# ospi_secure register map
Vendor: Texas Instruments
Peripheral module from a debugger description file (folder CC35X1E).
Registers are 32-bit, access per field, reset 0x0 unless marked. A register's access mark holds for its fields unless they carry their own. Offsets are as the file gives them; lines under a group give offsets from that group; [hi:lo] are bit positions; {n}, {i} and the like mark numbered series; 'fields as' and 'values as' point back to an identical list; <NAME> marks a mode.

## ospi_secure
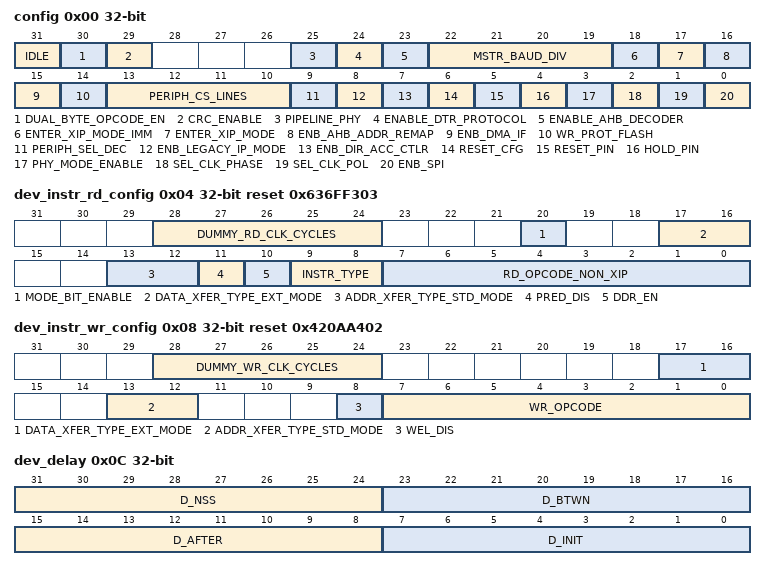
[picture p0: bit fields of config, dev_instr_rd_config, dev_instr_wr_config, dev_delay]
0x00 config reset not defined — Octal-SPI Configuration Register
  [31] IDLE ro — Serial interface and low level SPI pipeline is IDLE: This is a STATUS read-only bit. Note this is a retimed signal, so there will be some inherent delay on the generation of this status signal.
    0=DISABLE; 1=ENABLE
  [30] DUAL_BYTE_OPCODE_EN rw — Dual-byte Opcode Mode enable bit This bit is to be set in case the target Flash Device supports dual byte opcode (i.e. Macronix MX25). It is applicable for Octal I/O Mode or Protocol only so should be set back to low if the device is configured to work in another SPI Mode. If enabled, the supplementing bytes are taken from Opcode Extension Register (Lower) and from Opcode Extension Register (Upper).
    0=DISABLE; 1=ENABLE
  [29] CRC_ENABLE rw — CRC enable bit This bit is to be set in case the target Flash Device supports CRC (Macronix MX25). It is applicable for Octal DDR Protocol only so should be set back to low if the device is configured to work in another SPI Mode.
    0=DISABLE; 1=ENABLE
  [25] PIPELINE_PHY rw — Pipeline PHY Mode enable: This bit is relevant only for configuration with PHY Module. It should be asserted to '1' between consecutive PHY pipeline reads transfers and de-asserted to '0' otherwise.
    0=DISABLE; 1=ENABLE
  [24] ENABLE_DTR_PROTOCOL rw — Enable DTR Protocol: This bit should be set if device is configured to work in DTR protocol.
    0=DISABLE; 1=ENABLE
  [23] ENABLE_AHB_DECODER rw — Enable AHB Decoder: Value=0 : Active slave is selected based on Peripheral Chip Select Lines (bits [13:10]). Value=1 Active slave is selected based on actual AHB address (the partition for each device is calculated with respect to bits [28:21] of Device Size Configuration Register)
    0=DISABLE; 1=ENABLE
  [22:19] MSTR_BAUD_DIV rw — Master Mode Baud Rate Divisor: SPI baud rate = (master reference clock) baud_rate_divisor. The baud rate is the clock rate divided by 2 multiplied by (Divisor + 1). Meaning, when Divisor Value is set to 0,1,2,..15 it sets the baud rate is the clock rate divided by 2, 4, 6,..32 respectively
    0=MINIMUM (Smallest value); 15=MAXIMUM (Highest possible value)
  [18] ENTER_XIP_MODE_IMM rw — Enter XIP Mode immediately: Value=0 : If XIP is enabled, then setting to 0 will cause the controller to exit XIP mode on the next READ instruction. Value=1 : Operate the device in XIP mode immediately Use this register when the external device wakes up in XIP mode (as per the contents of its non- volatile configuration register). The controller will assume the next READ instruction will be passed to the device as an XIP instruction, and therefore will not require the READ opcode to be transferred. Note: To exit XIP mode, this bit should be set to 0. This will take effect in the attached device only after the next READ instruction is executed. Software therefore should ensure that at least one READ instruction is requested after resetting this bit in order to be sure that XIP mode is exited.
    0=DISABLE; 1=ENABLE
  [17] ENTER_XIP_MODE rw — Enter XIP Mode on next READ: Value=0 : If XIP is enabled, then setting to 0 will cause the controller to exit XIP mode on the next READ instruction. Value=1 : If XIP is disabled, then setting to ?1? will inform the controller that the device is ready to enter XIP on the next READ instruction. The controller will therefore send the appropriate command sequence, including mode bits to cause the device to enter XIP mode. Use this register after the controller has ensured the FLASH device has been configured to be ready to enter XIP mode. Note : To exit XIP mode, this bit should be set to 0. This will take effect in the attached device only AFTER the next READ instruction is executed. Software should therefore ensure that at least one READ instruction is requested after resetting this bit before it can be sure XIP mode in the device is exited.
    0=DISABLE; 1=ENABLE
  [16] ENB_AHB_ADDR_REMAP rw — Enable AHB Address Re-mapping: (Direct Access Mode Only) When set to 1, the incoming AHB address will be adapted and sent to the FLASH device as (address + N), where N is the value stored in the remap address register.
    0=DISABLE; 1=ENABLE
  [15] ENB_DMA_IF rw — Enable DMA Peripheral Interface: Set to 1 to enable the DMA handshaking logic. When enabled the controller will trigger DMA transfer requests via the DMA peripheral interface. Set to 0 to disable
    0=DISABLE; 1=ENABLE
  [14] WR_PROT_FLASH rw — Write Protect Flash Pin: Set to drive the Write Protect pin of the FLASH device. This is resynchronized to the generated memory clock as necessary.
    0=DISABLE; 1=ENABLE
  [13:10] PERIPH_CS_LINES rw — Peripheral Chip Select Lines: Peripheral chip select lines If pdec = 0, ss[3:0] are output thus: ss[3:0] n_ss_out[3:0] xxx0 1110 xx01 1101 x011 1011 0111 0111 1111 1111 (no peripheral selected) else ss[3:0] directly drives n_ss_out[3:0]
    values as MSTR_BAUD_DIV
  [9] PERIPH_SEL_DEC rw — Peripheral select decode:
    0=DISABLE (only 1 of 4 selects n_ss_out[3:0] is active 1 : allow external 4-to-16 decode (n_ss_out = ss)); 1=ENABLE (allow external 4-to-16 decode (n_ss_out = ss))
  [8] ENB_LEGACY_IP_MODE rw — Legacy IP Mode Enable:
    0=DISABLE (Use Direct Access Controller/Indirect Access Controller 1 : legacy Mode is enabled. In this mode, any write to the controller via the AHB interface is serialized and sent to the FLASH device. Any valid AHB read will pop the internal RX-FIFO, retrieving data that was forwarded by the external FLASH device on the SPI lines,4,2 or 1 byte transfers are permitted and controlled via the HSIZE input.); 1=ENABLE (legacy Mode is enabled. In this mode, any write to the controller via the AHB interface is serialized and sent to the FLASH device. Any valid AHB read will pop the internal RX-FIFO, retrieving data that was forwarded by the external FLASH device on the SPI lines,4,2 or 1 byte transfers are permitted and controlled via the HSIZE input.)
  [7] ENB_DIR_ACC_CTLR rw — Enable Direct Access Controller:
    0=DISABLE (disable the Direct Access Controller once current transfer of the data word (FF_W) is complete. 1 : enable the Direct Access Controller When the Direct Access Controller and Indirect Access Controller are both disabled, all AHB requested are completed with an error response.); 1=ENABLE (enable the Direct Access Controller When the Direct Access Controller and Indirect Access Controller are both disabled, all AHB requested are completed with an error response.)
  [6] RESET_CFG rw — RESET pin configuration: 0 = RESET feature on DQ3 pin of the device 1 = RESET feature on dedicated pin of the device (controlling of 5th bit influences on reset_out output)
    0=DISABLE; 1=ENABLE
  [5] RESET_PIN rw — Set to drive the RESET pin of the FLASH device and reset for de-activation of the RESET pin feature
    0=DISABLE; 1=ENABLE
  [4] HOLD_PIN rw — Set to drive the HOLD pin of the FLASH device and reset for de-activation of the HOLD pin feature
    0=DISABLE; 1=ENABLE
  [3] PHY_MODE_ENABLE rw — PHY mode enable: When enabled, the controller is informed that PHY Module is to be used for handling SPI transfers. This bit is relevant only for configuration with PHY Module.
    0=DISABLE; 1=ENABLE
  [2] SEL_CLK_PHASE rw — Select Clock Phase: Selects whether the clock is in an active or inactive phase outside the SPI word.
    0=DISABLE (the SPI clock is active outside the word 1 : the SPI clock is inactive outside the word); 1=ENABLE (the SPI clock is inactive outside the word)
  [1] SEL_CLK_POL rw — Clock polarity outside SPI word:
    0=DISABLE (the SPI clock is quiescent low 1 : the SPI clock is quiescent high); 1=ENABLE (the SPI clock is quiescent high)
  [0] ENB_SPI rw — Octal-SPI Enable:
    0=DISABLE (disable the Octal-SPI, once current transfer of the data word (FF_W) is complete. 1 : enable the Octal-SPI, when spi_enable = 0, all output enables are inactive and all pins are set to input mode.); 1=ENABLE (enable the Octal-SPI, when spi_enable = 0, all output enables are inactive and all pins are set to input mode.)
0x04 dev_instr_rd_config reset 0x636FF303 (reset mask 0xFFEFF3FF) — Device Read Instruction Configuration Register
  [28:24] DUMMY_RD_CLK_CYCLES rw — Dummy Read Clock Cycles: Number of dummy clock cycles required by device for read instruction.
    0=MINIMUM (Smallest value); 31=MAXIMUM (Highest possible value)
  [20] MODE_BIT_ENABLE rw — Mode Bit Enable: Set this field to 1 to ensure that the mode bits as defined in the Mode Bit Configuration register are sent following the address bytes.
    0=DISABLE; 1=ENABLE
  [17:16] DATA_XFER_TYPE_EXT_MODE rw — Data Transfer Type for Standard SPI modes: 0 : SIO mode data is shifted to the device on DQ0 only and from the device on DQ1 only 1 : Used for Dual Input/Output instructions. For data transfers, DQ0 and DQ1 are used as both inputs and outputs. 2 : Used for Quad Input/Output instructions. For data transfers, DQ0,DQ1,DQ2 and DQ3 are used as both inputs and outputs. 3 : Used for Quad Input/Output instructions. For data transfers, DQ[7:0] are used as both inputs and outputs.
    0=MINIMUM (Smallest value); 3=MAXIMUM (Highest possible value)
  [13:12] ADDR_XFER_TYPE_STD_MODE rw — Address Transfer Type for Standard SPI modes: 0 : Addresses can be shifted to the device on DQ0 only 1 : Addresses can be shifted to the device on DQ0 and DQ1 only 2 : Addresses can be shifted to the device on DQ0, DQ1, DQ2 and DQ3 3 : Addresses can be shifted to the device on DQ[7:0]
    values as DATA_XFER_TYPE_EXT_MODE
  [11] PRED_DIS rw — Predicted Read Disable Bit: Disable generation of predicted read when doing read accesses using Direct Mode
    0=DISABLE; 1=ENABLE
  [10] DDR_EN rw — DDR Enable: This is to inform that opcode from rd_opcode_non_xip_fld is compliant with one of the DDR READ Commands
    0=DISABLE; 1=ENABLE
  [9:8] INSTR_TYPE rw — Instruction Type: 0 : Use Standard SPI mode (instruction always shifted into the device on DQ0 only) 1 : Use DIO-SPI mode (Instructions always sent on DQ0 and DQ1) 2 : Use QIO-SPI mode (Instructions always sent on DQ0, DQ1, DQ2 and DQ3) 3 : Use Octal-IO-SPI mode (Instructions always sent on DQ[7:0])
    values as DATA_XFER_TYPE_EXT_MODE
  [7:0] RD_OPCODE_NON_XIP rw — Read Opcode in non-XIP mode: Read Opcode to use when not in XIP mode
    0=MINIMUM (Smallest value); 255=MAXIMUM (Highest possible value)
0x08 dev_instr_wr_config reset 0x420AA402 (reset mask 0xFFFFFEFF) — Device Write Instruction Configuration Register
  [28:24] DUMMY_WR_CLK_CYCLES rw — Dummy Write Clock Cycles: Number of dummy clock cycles required by device for write instruction.
    values as dev_instr_rd_config.DUMMY_RD_CLK_CYCLES
  [17:16] DATA_XFER_TYPE_EXT_MODE rw — Data Transfer Type for Standard SPI modes: 0 : SIO mode data is shifted to the device on DQ0 only and from the device on DQ1 only 1 : Used for Dual Input/Output instructions. For data transfers, DQ0 and DQ1 are used as both inputs and outputs. 2 : Used for Quad Input/Output instructions. For data transfers, DQ0,DQ1,DQ2 and DQ3 are used as both inputs and outputs. 3 : Used for Quad Input/Output instructions. For data transfers, DQ[7:0] are used as both inputs and outputs.
    values as dev_instr_rd_config.DATA_XFER_TYPE_EXT_MODE
  [13:12] ADDR_XFER_TYPE_STD_MODE rw — Address Transfer Type for Standard SPI modes: 0 : Addresses can be shifted to the device on DQ0 only 1 : Addresses can be shifted to the device on DQ0 and DQ1 only 2 : Addresses can be shifted to the device on DQ0, DQ1, DQ2 and DQ3 3 : Addresses can be shifted to the device on DQ[7:0]
    values as dev_instr_rd_config.DATA_XFER_TYPE_EXT_MODE
  [8] WEL_DIS rw — WEL Disable: This is to turn off automatic issuing of WEL Command before write operation for DAC or INDAC
    0=DISABLE; 1=ENABLE
  [7:0] WR_OPCODE rw — Write Opcode
    values as dev_instr_rd_config.RD_OPCODE_NON_XIP
0x0C dev_delay rw — Octal-SPI Device Delay Register: This register is used to introduce relative delays into the generation of the master output signals. All timings are defined in cycles of the SPI REFERENCE CLOCK/ext_clk, defined in this table as SPI master ref clock.
  [all] fields
    values as dev_instr_rd_config.RD_OPCODE_NON_XIP
  [31:24] D_NSS — Clock Delay for Chip Select Deassert: Delay in master reference clocks for the length that the master mode chip select outputs are de-asserted between transactions. The minimum delay is always SCLK period to ensure the chip select is never re-asserted within an SCLK period.
  [23:16] D_BTWN — Clock Delay for Chip Select Deactivation: Delay in master reference clocks between one chip select being de-activated and the activation of another. This is used to ensure a quiet period between the selection of two different slaves and requires the transmit FIFO to be empty.
  [15:8] D_AFTER — Clock Delay for Last Transaction Bit: Delay in master reference clocks between last bit of current transaction and deasserting the device chip select (n_ss_out). By default, the chip select will be deasserted on the cycle following the completion of the current transaction.
  [7:0] D_INIT — Clock Delay with n_ss_out: Delay in master reference clocks between setting n_ss_out low and first bit transfer.
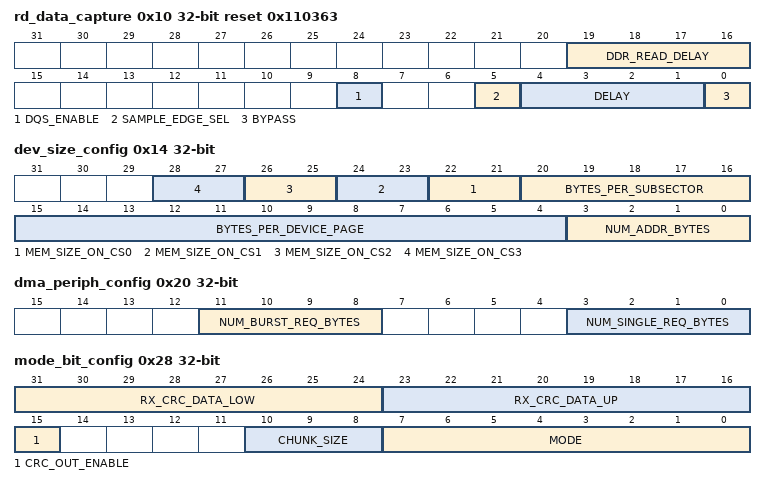
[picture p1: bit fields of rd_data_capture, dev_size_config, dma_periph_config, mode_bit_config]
0x10 rd_data_capture reset 0x110363 — Read Data Capture Register
  [19:16] DDR_READ_DELAY rw — DDR read delay: Delay the transmitted data by the programmed number of ref_clk cycles.This field is only relevant when DDR Read Command is executed. Otherwise can be ignored.
    values as config.MSTR_BAUD_DIV
  [8] DQS_ENABLE rw — DQS enable bit: If enabled, signal from DQS input is driven into RX DLL and is used for data capturing in PHY Mode rather than internally generated gated ref_clk..
    0=DISABLE; 1=ENABLE
  [5] SAMPLE_EDGE_SEL rw — Sample edge selection: Choose edge on which data outputs from flash memory will be sampled
    0=DISABLE; 1=ENABLE
  [4:1] DELAY rw — Read Delay: Delay the read data capturing logic by the programmed number of ref_clk cycles
    values as config.MSTR_BAUD_DIV
  [0] BYPASS rw — Bypass the adapted loopback clock circuit
    0=DISABLE; 1=ENABLE
0x14 dev_size_config reset not defined — Device Size Configuration Register
  [2n+22:2n+21] MEM_SIZE_ON_CS{n} rw (n=0..3) — Size of Flash Device connected to CS[{n}] pin: Value=00 : size of 512Mb. Value=01 : size of 1Gb. Value=10 : size of 2Gb. Value=11 : size of 4Gb.
    values as dev_instr_rd_config.DATA_XFER_TYPE_EXT_MODE
  [20:16] BYTES_PER_SUBSECTOR rw — Number of bytes per Block. This is required by the controller for performing the write protection logic. The number of bytes per block must be a power of 2 number.
    values as dev_instr_rd_config.DUMMY_RD_CLK_CYCLES
  [15:4] BYTES_PER_DEVICE_PAGE rw — Number of bytes per device page. This is required by the controller for performing FLASH writes up to and across page boundaries.
    0=MINIMUM (Smallest value); 0xFFF=MAXIMUM (Highest possible value)
  [3:0] NUM_ADDR_BYTES rw — Number of address bytes. A value of 0 indicates 1 byte.
    values as config.MSTR_BAUD_DIV
0x18 sram_partition_cfg reset 0x8080 — SRAM Partition Configuration Register
  [7:0] THRESHOLD rw — Defines the size of the indirect read partition in the SRAM, in units of SRAM locations. By default, half of the SRAM is reserved for indirect read operation, and half for indirect write. The size of this register will scale with the depth of the SRAM.
0x1C ind_ahb_addr_trigger rw — Indirect AHB Address Trigger Register
  [31:0] ADDR — This is the base address that will be used by the AHB controller. When the incoming AHB read access address matches a range of addresses from this trigger address to the trigger address + 15, then the AHB request will be completed by fetching data from the Indirect Controllers SRAM.
    0=MINIMUM (Smallest value); 0xFFFFFFFF=MAXIMUM (Highest possible value)
0x20 dma_periph_config — DMA Peripheral Configuration Register
  [11:8] NUM_BURST_REQ_BYTES rw — Number of Burst Bytes: Number of bytes in a burst type request on the DMA peripheral request. A programmed value of 0 represents a single byte. This should be setup before starting the indirect read or write operation. The actual number of bytes used is 2**(value in this register) which will simplify implementation.
    values as config.MSTR_BAUD_DIV
  [3:0] NUM_SINGLE_REQ_BYTES rw — Number of Single Bytes: Number of bytes in a single type request on the DMA peripheral request. A programmed value of 0 represents a single byte. This should be setup before starting the indirect read or write operation. The actual number of bytes used is 2**(value in this register) which will simplify implementation.
    values as config.MSTR_BAUD_DIV
0x24 remap_addr rw — Remap Address Register
  [31:0] VALUE — This register is used to remap an incoming AHB address to a different address used by the FLASH device.
    values as ind_ahb_addr_trigger.ADDR
0x28 mode_bit_config reset not defined — Mode Bit Configuration Register
  [31:24] RX_CRC_DATA_LOW ro — RX CRC data (lower) The first CRC byte returned after RX data chunk.
    values as dev_instr_rd_config.RD_OPCODE_NON_XIP
  [23:16] RX_CRC_DATA_UP ro — RX CRC data (upper) The second CRC byte returned after RX data chunk.
    values as dev_instr_rd_config.RD_OPCODE_NON_XIP
  [15] CRC_OUT_ENABLE rw — CRC# output enable bit When enabled, the controller expects the Flash Device to toggle CRC data on both SPI clock edges in CRC->CRC# sequence and calculates CRC compliance accordingly.
    0=DISABLE; 1=ENABLE
  [10:8] CHUNK_SIZE rw — It defines size of chunk after which CRC data is expected to show up on the SPI interface for write and read data transfers.
    0=MINIMUM (Smallest value); 7=MAXIMUM (Highest possible value)
  [7:0] MODE rw — These are the 8 mode bits that are sent to the device following the address bytes if mode bit transmission has been enabled.
    values as dev_instr_rd_config.RD_OPCODE_NON_XIP
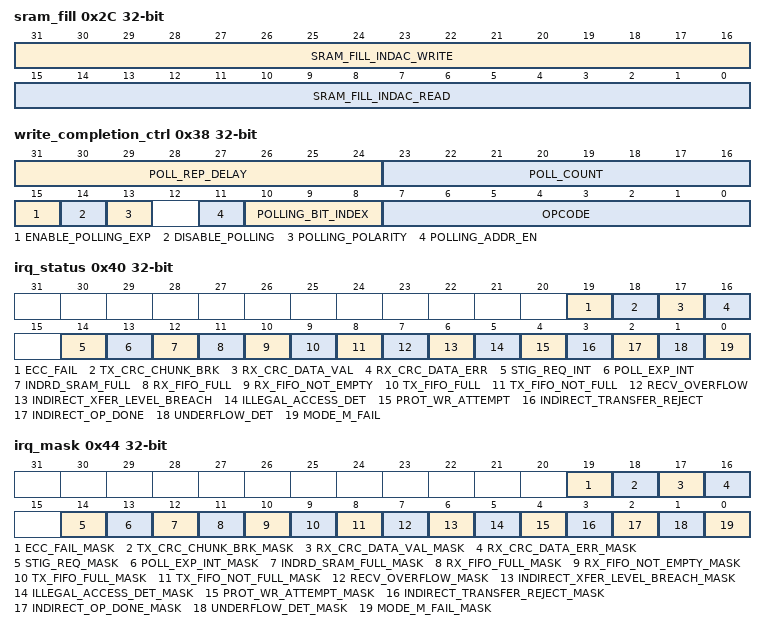
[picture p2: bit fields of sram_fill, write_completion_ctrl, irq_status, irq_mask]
0x2C sram_fill ro
  [31:16] SRAM_FILL_INDAC_WRITE — SRAM Fill Level (Indirect Write Partition): Identifies the current fill level of the SRAM Indirect Write partition
    0=MINIMUM (Smallest value); 0xFFFF=MAXIMUM (Highest possible value)
  [15:0] SRAM_FILL_INDAC_READ — SRAM Fill Level (Indirect Read Partition): Identifies the current fill level of the SRAM Indirect Read partition
    values as SRAM_FILL_INDAC_WRITE
0x30 tx_thresh reset 0x21 — TX Threshold Register
  [4:0] LEVEL rw — Defines the level at which the small TX FIFO not full interrupt is generated
    values as dev_instr_rd_config.DUMMY_RD_CLK_CYCLES
0x34 rx_thresh reset 0x21 — RX Threshold Register
  [4:0] LEVEL rw — Defines the level at which the small RX FIFO not empty interrupt is generated
    values as dev_instr_rd_config.DUMMY_RD_CLK_CYCLES
0x38 write_completion_ctrl reset not defined — Write Completion Control Register: This register defines how the controller will poll the device following a write transfer
  [31:24] POLL_REP_DELAY rw — Defines additional delay for maintain Chip Select de-asserted during auto-polling phase
    values as dev_instr_rd_config.RD_OPCODE_NON_XIP
  [23:16] POLL_COUNT rw — Defines the number of times the controller should expect to see a true result from the polling in successive reads of the device register.
    values as dev_instr_rd_config.RD_OPCODE_NON_XIP
  [15] ENABLE_POLLING_EXP rw — Set to '1' for enabling auto-polling expiration.
    0=DISABLE; 1=ENABLE
  [14] DISABLE_POLLING rw — This switches off the automatic polling function
    0=DISABLE; 1=ENABLE
  [13] POLLING_POLARITY rw — Defines the polling polarity. If '1', then the write transfer to the device will be complete if the polled bit is equal to '1'. If '0', then the write transfer to the device will be complete if the polled bit is equal to '0'.
    0=DISABLE; 1=ENABLE
  [11] POLLING_ADDR_EN rw — Enables address phase of auto-polling (Read Status) command.
    0=DISABLE; 1=ENABLE
  [10:8] POLLING_BIT_INDEX rw — Defines the bit index that should be polled. A value of 010 means that bit 2 of the returned data will be polled for.A value of 111 means that bit 7 of the returned data will be polled for.
    values as mode_bit_config.CHUNK_SIZE
  [7:0] OPCODE rw — Defines the opcode that should be issued by the controller when it is automatically polling for device program completion. This command is issued followed all device write operations. By default, this will poll the standard device STATUS register using opcode 0x05
    values as dev_instr_rd_config.RD_OPCODE_NON_XIP
0x3C no_of_polls_bef_exp rw reset 0xFFFFFFFF — Polling Expiration Register
  [31:0] NO_OF_POLLS_BEF_EXP — Number of polls cycles before expiration
    values as ind_ahb_addr_trigger.ADDR
0x40 irq_status — Interrupt Status Register: The status fields in this register are set when the described event occurs and the interrupt is enabled in the mask register. When any of these bit fields are set, the interrupt output is asserted high. The fields are each cleared by writing a 1 to the field. Note that bit fields 6 thru 10 are only valid when legacy SPI mode is active.
  [19] ECC_FAIL rw — ECC failure This interrupt informs the system that Flash Device reported ECC error.
    0=DISABLE; 1=ENABLE
  [18] TX_CRC_CHUNK_BRK rw — TX CRC chunk was broken This interrupt informs the system that program page SPI transfer was discontinued somewhere inside the chunk.
    0=DISABLE; 1=ENABLE
  [17] RX_CRC_DATA_VAL rw — RX CRC data valid New RX CRC data was captured from Flash Device
    0=DISABLE; 1=ENABLE
  [16] RX_CRC_DATA_ERR rw — RX CRC data error CRC data from Flash Device does not correspond to the one dynamically calculated by the controller.
    0=DISABLE; 1=ENABLE
  [14] STIG_REQ_INT rw — The controller is ready for getting another STIG request.
    0=DISABLE; 1=ENABLE
  [13] POLL_EXP_INT rw — The maximum number of programmed polls cycles is expired
    0=DISABLE; 1=ENABLE
  [12] INDRD_SRAM_FULL rw — Indirect Read Partition overflow: Indirect Read Partition of SRAM is full and unable to immediately complete indirect operation
    0=DISABLE; 1=ENABLE
  [11] RX_FIFO_FULL rw — Small RX FIFO full: Current FIFO status can be ignored in non-SPI legacy mode
    0=DISABLE (FIFO is not full 1 : FIFO is full); 1=ENABLE (FIFO is full)
  [10] RX_FIFO_NOT_EMPTY rw — Small RX FIFO not empty: Current FIFO status can be ignored in non-SPI legacy mode
    0=DISABLE (FIFO has less than RX THRESHOLD entries, 1 : FIFO has >= THRESHOLD entries); 1=ENABLE (FIFO has >= THRESHOLD entries)
  [9] TX_FIFO_FULL rw — Small TX FIFO full: Current FIFO status can be ignored in non-SPI legacy mode
    0=DISABLE (FIFO is not full, 1 : FIFO is full); 1=ENABLE (FIFO is full)
  [8] TX_FIFO_NOT_FULL rw — Small TX FIFO not full: Current FIFO status can be ignored in non-SPI legacy mode
    0=DISABLE (FIFO has >= THRESHOLD entries, 1 : FIFO has less than THRESHOLD entries); 1=ENABLE (FIFO has less than THRESHOLD entries)
  [7] RECV_OVERFLOW rw — Receive Overflow: This should only occur in Legacy SPI mode. Set if an attempt is made to push the RX FIFO when it is full. This bit is reset only by a system reset and cleared only when this register is read. If a new push to the RX FIFO occurs coincident with a register read this flag will remain set.
    0=DISABLE (no overflow has been detected. 1 : an overflow has occurred.); 1=ENABLE (an overflow has occurred.)
  [6] INDIRECT_XFER_LEVEL_BREACH rw — Indirect Transfer Watermark Level Breached
    0=DISABLE; 1=ENABLE
  [5] ILLEGAL_ACCESS_DET rw — Illegal AHB access has been detected. AHB wrapping bursts and the use of SPLIT/RETRY accesses will cause this error interrupt to trigger.
    0=DISABLE; 1=ENABLE
  [4] PROT_WR_ATTEMPT rw — Write to protected area was attempted and rejected.
    0=DISABLE; 1=ENABLE
  [3] INDIRECT_TRANSFER_REJECT rw — Indirect operation was requested but could not be accepted. Two indirect operations already in storage.
    0=DISABLE; 1=ENABLE
  [2] INDIRECT_OP_DONE rw — Indirect Operation Complete: Controller has completed last triggered indirect operation
    0=DISABLE; 1=ENABLE
  [1] UNDERFLOW_DET rw — Underflow Detected:
    0=DISABLE (no underflow has been detected 1 : underflow is detected and an attempt to transfer data is made when the small TX FIFO is empty. This may occur when AHB write data is being supplied too slowly to keep up with the requested write operation This bit is reset only by a system reset and cleared only when the register is read.); 1=ENABLE (underflow is detected and an attempt to transfer data is made when the small TX FIFO is empty. This may occur when AHB write data is being supplied too slowly to keep up with the requested write operation This bit is reset only by a system reset and cleared only when the register is read.)
  [0] MODE_M_FAIL rw — Mode M Failure: Mode M failure indicates the voltage on pin n_ss_in is inconsistent with the SPI mode. Set =1 if n_ss_in is low in master mode (multi-master contention). These conditions will clear the spi_enable bit and disable the SPI. This bit is reset only by a system reset and cleared only when this register is read.
    0=DISABLE (no mode fault has been detected 1 : a mode fault has occurred); 1=ENABLE (a mode fault has occurred)
0x44 irq_mask — Interrupt Mask: 0 : the interrupt for the corresponding interrupt status register bit is disabled. 1 : the interrupt for the corresponding interrupt status register bit is enabled.
  [all] fields
    0=DISABLE; 1=ENABLE
  [19] ECC_FAIL_MASK rw — ECC failure Mask
  [18] TX_CRC_CHUNK_BRK_MASK rw — TX CRC chunk was broken Mask
  [17] RX_CRC_DATA_VAL_MASK rw — RX CRC data valid Mask
  [16] RX_CRC_DATA_ERR_MASK rw — RX CRC data error Mask
  [14] STIG_REQ_MASK rw — STIG request completion Mask
  [13] POLL_EXP_INT_MASK rw — Polling expiration detected Mask
  [12] INDRD_SRAM_FULL_MASK rw — Indirect Read Partition overflow mask
  [11] RX_FIFO_FULL_MASK rw — Small RX FIFO full Mask
  [10] RX_FIFO_NOT_EMPTY_MASK rw — Small RX FIFO not empty Mask
  [9] TX_FIFO_FULL_MASK rw — Small TX FIFO full Mask
  [8] TX_FIFO_NOT_FULL_MASK rw — Small TX FIFO not full Mask
  [7] RECV_OVERFLOW_MASK rw — Receive Overflow Mask
  [6] INDIRECT_XFER_LEVEL_BREACH_MASK rw — Transfer Watermark Breach Mask
  [5] ILLEGAL_ACCESS_DET_MASK rw — Illegal Access Detected Mask
  [4] PROT_WR_ATTEMPT_MASK rw — Protected Area Write Attempt Mask
  [3] INDIRECT_TRANSFER_REJECT_MASK rw — Indirect Read Reject Mask
  [2] INDIRECT_OP_DONE_MASK rw — Indirect Complete Mask
  [1] UNDERFLOW_DET_MASK rw — Underflow Detected Mask
  [0] MODE_M_FAIL_MASK rw — Mode M Failure Mask
0x50 lower_wr_prot rw — Lower Write Protection Register
  [31:0] SUBSECTOR — The block number that defines the lower block in the range of blocks that is to be locked from writing. The definition of a block in terms of number of bytes is programmable via the Device Size Configuration register.
    values as ind_ahb_addr_trigger.ADDR
0x54 upper_wr_prot rw — Upper Write Protection Register
  [31:0] SUBSECTOR — The block number that defines the upper block in the range of blocks that is to be locked from writing. The definition of a block in terms of number of bytes is programmable via the Device Size Configuration register.
    values as ind_ahb_addr_trigger.ADDR
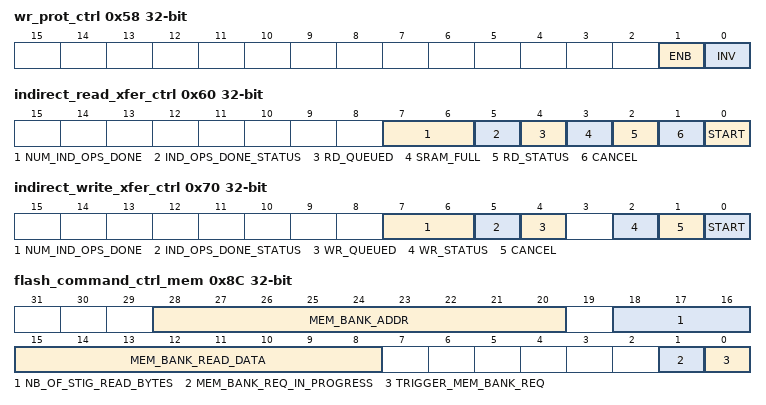
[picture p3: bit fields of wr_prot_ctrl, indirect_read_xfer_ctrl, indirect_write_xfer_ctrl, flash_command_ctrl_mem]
0x58 wr_prot_ctrl — Write Protection Control Register
  [1] ENB rw — Write Protection Enable Bit: When set to 1, any AHB write access with an address within the protection region defined in the lower and upper write protection registers is rejected. An AHB error response is generated and an interrupt source triggered. When set to 0, the protection region is disabled.
    0=DISABLE; 1=ENABLE
  [0] INV rw — Write Protection Inversion Bit: When set to 1, the protection region defined in the lower and upper write protection registers is inverted meaning it is the region that the system is permitted to write to. When set to 0, the protection region defined in the lower and upper write protection registers is the region that the system is not permitted to write to.
    0=DISABLE; 1=ENABLE
0x60 indirect_read_xfer_ctrl — Indirect Read Transfer Control Register
  [7:6] NUM_IND_OPS_DONE ro — This field contains the number of indirect operations which have been completed. This is used in conjunction with the indirect completion status field (bit 5). It is incremented by hardware when an indirect operation has completed. Write a 1 to bit 5 of this register to decrement it.
    values as dev_instr_rd_config.DATA_XFER_TYPE_EXT_MODE
  [5] IND_OPS_DONE_STATUS rw — Indirect Completion Status: This field is set to 1 when an indirect operation has completed. Write a 1 to this field to clear it.
    0=DISABLE; 1=ENABLE
  [4] RD_QUEUED ro — Two indirect read operations have been queued
    0=DISABLE; 1=ENABLE
  [3] SRAM_FULL rw — SRAM Full: SRAM full and unable to immediately complete an indirect operation. Write a 1 to this field to clear it.\"; indirect operation (status)
    0=DISABLE; 1=ENABLE
  [2] RD_STATUS ro — Indirect Read Status: Indirect read operation in progress (status)
    0=DISABLE; 1=ENABLE
  [1] CANCEL wo — Cancel Indirect Read: Writing a 1 to this bit will cancel all ongoing indirect read operations.
    0=DISABLE; 1=ENABLE
  [0] START wo — Start Indirect Read: Writing a 1 to this bit will trigger an indirect read operation. The assumption is that the indirect start address and the indirect number of bytes register is setup before triggering the indirect read operation.
    0=DISABLE; 1=ENABLE
0x64 indirect_read_xfer_watermark rw — Indirect Read Transfer Watermark Register
  [31:0] LEVEL — Watermark Value: This represents the minimum fill level of the SRAM before a DMA peripheral access is permitted. When the SRAM fill level passes the watermark, an interrupt is also generated. This field can be disabled by writing a value of all zeroes.
    values as ind_ahb_addr_trigger.ADDR
0x68 indirect_read_xfer_start rw — Indirect Read Transfer Start Address Register
  [31:0] ADDR — This is the start address from which the indirect access will commence its READ operation.
    values as ind_ahb_addr_trigger.ADDR
0x6C indirect_read_xfer_num_bytes rw — Indirect Read Transfer Number Bytes Register
  [31:0] VALUE — This is the number of bytes that the indirect access will consume. This can be bigger than the configured size of SRAM.
    values as ind_ahb_addr_trigger.ADDR
0x70 indirect_write_xfer_ctrl — Indirect Write Transfer Control Register
  [7:6] NUM_IND_OPS_DONE ro — This field contains the number of indirect operations which have been completed. This is used in conjunction with the indirect completion status field (bit 5). It is incremented by hardware when an indirect operation has completed. Write a 1 to bit 5 of this register to decrement it.
    values as dev_instr_rd_config.DATA_XFER_TYPE_EXT_MODE
  [5] IND_OPS_DONE_STATUS rw — Indirect Completion Status: This field is set to 1 when an indirect operation has completed. Write a 1 to this field to clear it.
    0=DISABLE; 1=ENABLE
  [4] WR_QUEUED ro — Two indirect write operations have been queued
    0=DISABLE; 1=ENABLE
  [2] WR_STATUS ro — Indirect Write Status: Indirect write operation in progress (status)
    0=DISABLE; 1=ENABLE
  [1] CANCEL wo — Cancel Indirect Write: Writing a 1 to this bit will cancel all ongoing indirect write operations.
    0=DISABLE; 1=ENABLE
  [0] START wo — Start Indirect Write: Writing a 1 to this bit will trigger an indirect write operation. The assumption is that the indirect start address and the indirect number of bytes register is setup before triggering the indirect write operation.
    0=DISABLE; 1=ENABLE
0x74 indirect_write_xfer_watermark rw reset 0xFFFFFFFF — Indirect Write Transfer Watermark Register
  [31:0] LEVEL — Watermark Value: This represents the maximum fill level of the SRAM before a DMA peripheral access is permitted. When the SRAM fill level falls below the watermark, an interrupt is also generated. This field can be disabled by writing a value of all ones.
    values as ind_ahb_addr_trigger.ADDR
0x78 indirect_write_xfer_start rw — Indirect Write Transfer Start Address Register
  [31:0] ADDR — Start of Indirect Access: This is the start address from which the indirect access will commence its READ operation.
    values as ind_ahb_addr_trigger.ADDR
0x7C indirect_write_xfer_num_bytes rw — Indirect Write Transfer Number Bytes Register
  [31:0] VALUE — Indirect Number of Bytes: This is the number of bytes that the indirect access will consume. This can be bigger than the configured size of SRAM.
    values as ind_ahb_addr_trigger.ADDR
0x80 indirect_trigger_addr_range reset 0x44 — Indirect Trigger Address Range Register
  [3:0] IND_RANGE_WIDTH rw — This is the address offset of Indirect Trigger Address Register.
    values as config.MSTR_BAUD_DIV
0x8C flash_command_ctrl_mem — Flash Command Control Memory Register
  [28:20] MEM_BANK_ADDR rw — The address of the Memory Bank which data will be read from.
    0=MINIMUM (Smallest value); 0x1FF=MAXIMUM (Highest possible value)
  [18:16] NB_OF_STIG_READ_BYTES rw — It defines the number of read bytes for the extended STIG.
    values as mode_bit_config.CHUNK_SIZE
  [15:8] MEM_BANK_READ_DATA ro — Last requested data from the STIG Memory Bank.
    values as dev_instr_rd_config.RD_OPCODE_NON_XIP
  [1] MEM_BANK_REQ_IN_PROGRESS ro — Memory Bank data request in progress.
    0=DISABLE; 1=ENABLE
  [0] TRIGGER_MEM_BANK_REQ wo — Trigger the Memory Bank data request.
    0=DISABLE; 1=ENABLE
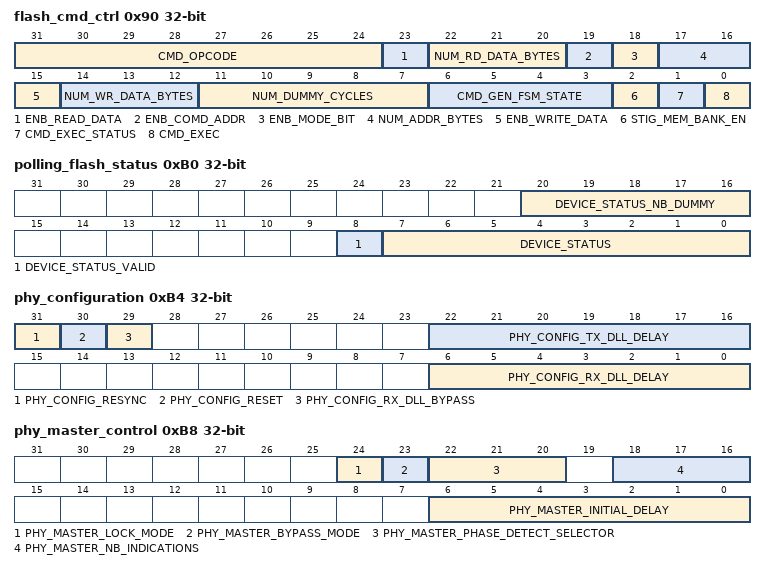
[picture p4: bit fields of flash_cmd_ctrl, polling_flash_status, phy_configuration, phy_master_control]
0x90 flash_cmd_ctrl — Flash Command Control Register
  [31:24] CMD_OPCODE rw — Command Opcode: The command opcode field should be setup before triggering the command. For example, 0x20 maps to SubSector Erase. Writing to the execute field (bit 0) of this register launches the command. NOTE : Using this approach to issue commands to the device will make use of the instruction type of the device instruction configuration register. If this field is set to 2'b00, then the command opcode, command address, command dummy bytes and command data will all be transferred in a serial fashion. If this field is set to 2'b01, then the command opcode, command address, command dummy bytes and command data will all be transferred in parallel using DQ0 and DQ1 pins. If this field is set to 2'b10, then the command opcode, command address, command dummy bytes and command data will all be transferred in parallel using DQ0, DQ1, DQ2 and DQ3 pins.
    values as dev_instr_rd_config.RD_OPCODE_NON_XIP
  [23] ENB_READ_DATA rw — Read Data Enable: Set to 1 if the command specified in the command opcode field (bits 31:24) requires read data bytes to be received from the device.
    0=DISABLE; 1=ENABLE
  [22:20] NUM_RD_DATA_BYTES rw — Number of Read Data Bytes: Up to 8 data bytes may be read using this command. Set to 0 for 1 byte and 7 for 8 bytes.
    values as mode_bit_config.CHUNK_SIZE
  [19] ENB_COMD_ADDR rw — Command Address Enable: Set to 1 if the command specified in bits 31:24 requires an address. This should be setup before triggering the command via writing a 1 to the execute field.
    0=DISABLE; 1=ENABLE
  [18] ENB_MODE_BIT rw — Mode Bit Enable: Set to 1 to ensure the mode bits as defined in the Mode Bit Configuration register are sent following the address bytes.
    0=DISABLE; 1=ENABLE
  [17:16] NUM_ADDR_BYTES rw — Number of Address Bytes: Set to the number of address bytes required (the address itself is programmed in the FLASH COMMAND ADDRESS REGISTERS). This should be setup before triggering the command via bit 0 of this register. 2'b00 : 1 address byte 2'b01 : 2 address bytes 2'b10 : 3 address bytes 2'b11 : 4 address bytes
    values as dev_instr_rd_config.DATA_XFER_TYPE_EXT_MODE
  [15] ENB_WRITE_DATA rw — Write Data Enable: Set to 1 if the command specified in the command opcode field requires write data bytes to be sent to the device.
    0=DISABLE; 1=ENABLE
  [14:12] NUM_WR_DATA_BYTES rw — Number of Write Data Bytes: Up to 8 Data bytes may be written using this command Set to 0 for 1 byte, 7 for 8 bytes.
    values as mode_bit_config.CHUNK_SIZE
  [11:7] NUM_DUMMY_CYCLES rw — Number of Dummy cycles: Set to the number of dummy cycles required. This should be setup before triggering the command via the execute field of this register.
    values as dev_instr_rd_config.DUMMY_RD_CLK_CYCLES
  [6:3] CMD_GEN_FSM_STATE ro — CMD_GEN_FSM_STATE is used to define the "Polling flag": If (CMD_GEN_FSM_STATE[6:3] = 0x7 or 0x8 or 0xa or 0xb ) then "Polling_flag"=1 Usage: In order to make sure a write to external device was done and ended successfully, following condition should be met: "Command execution in progress" (FLASH_CMD_CTRL.CMD_EXEC_STATUS) = 0 AND "Polling flag" is '0'. Design NOTE: Command gen FSM polling states are: CMD_GEN_FSM_STATE == POLL_STATUS_AFTER_WRITE (0x7) CMD_GEN_FSM_STATE == POLL_STATUS_AFTER_WRITE2 (0x8) CMD_GEN_FSM_STATE == POLL_STATUS_WAIT (0xb) CMD_GEN_FSM_STATE == LET_TXFIFO_EMPTY (0xa)
    0=IDLE; 1=SEND_ADDR_BYTES; 2=STIG_MODE_BYTE; 3=STIG_DUMMY_BYTES; 4=SEND_DATA; 5=SEND_STIG_DATA_LOWER; 6=SEND_STIG_DATA_UPPER; 7=POLL_STATUS_AFTER_WRITE; 8=POLL_STATUS_AFTER_WRITE2; 10=LET_TXFIFO_EMPTY; 11=POLL_STATUS_WAIT; 12=SEND_DATA_PIPE
  [2] STIG_MEM_BANK_EN rw — STIG Memory Bank enable bit.
    0=DISABLE; 1=ENABLE
  [1] CMD_EXEC_STATUS ro — Command execution in progress.
    0=DISABLE; 1=ENABLE
  [0] CMD_EXEC wo — Execute the command.
    0=DISABLE; 1=ENABLE
0x94 flash_cmd_addr rw — Flash Command Address Register
  [31:0] ADDR — Command Address: This should be setup before triggering the command with execute field (bit 0) of the Flash Command Control register. It is the address used by the command specified in the opcode field (bits 31:24) of the Flash Command Control register.
    values as ind_ahb_addr_trigger.ADDR
0xA0 flash_rd_data_lower ro — Flash Command Read Data Register (Lower)
  [31:0] DATA — This is the data that is returned by the flash device for any status or configuration read operation carried out by triggering the event in the control register. The register will be valid when the polling bit in the control register is low.
    values as ind_ahb_addr_trigger.ADDR
0xA4 flash_rd_data_upper ro — Flash Command Read Data Register (Upper)
  [31:0] DATA — This is the data that is returned by the FLASH device for any status or configuration read operation carried out by triggering the event in the control register. The register will be valid when the polling bit in the control register is low.
    values as ind_ahb_addr_trigger.ADDR
0xA8 flash_wr_data_lower rw — Flash Command Write Data Register (Lower)
  [31:0] DATA — Command Write Data Lower Byte: This is the command write data lower byte. This should be setup before triggering the command with execute field (bit 0) of the Flash Command Control register. It is the data that is to be written to the flash for any status or configuration write operation carried out by triggering the event in the Flash Command Control register.
    values as ind_ahb_addr_trigger.ADDR
0xAC flash_wr_data_upper rw — Flash Command Write Data Register (Upper)
  [31:0] DATA — Command Write Data Upper Byte: This is the command write data upper byte. This should be setup before triggering the command with execute field (bit 0) of the Flash Command Control register. It is the data that is to be written to the flash for any status or configuration write operation carried out by triggering the event in the Flash Command Control register.
    values as ind_ahb_addr_trigger.ADDR
0xB0 polling_flash_status
  [20:16] DEVICE_STATUS_NB_DUMMY rw — Number of dummy cycles for auto-polling
    values as dev_instr_rd_config.DUMMY_RD_CLK_CYCLES
  [8] DEVICE_STATUS_VALID ro — Device Status Valid: This should be set when value in bits from 7 to 0 is valid.
    0=DISABLE; 1=ENABLE
  [7:0] DEVICE_STATUS ro — Defines actual Status Register of Device
    values as dev_instr_rd_config.RD_OPCODE_NON_XIP
0xB4 phy_configuration reset not defined
  [31] PHY_CONFIG_RESYNC wo — This bit is used for re-synchronisation delay lines to update them with values from TX DLL Delay and RX DLL Delay fields.
    0=DISABLE; 1=ENABLE
  [30] PHY_CONFIG_RESET wo — DLL Reset bit: This bit is used for reset of Delay Lines by software.
    0=DISABLE; 1=ENABLE
  [29] PHY_CONFIG_RX_DLL_BYPASS rw — RX DLL Bypass: This field determines id RX DLL is bypassed.
    0=DISABLE; 1=ENABLE
  [22:16] PHY_CONFIG_TX_DLL_DELAY rw — TX DLL Delay: This field determines the number of delay elements to insert on data path between ref_clk and spi_clk.
    0=MINIMUM (Smallest value); 127=MAXIMUM (Highest possible value)
  [6:0] PHY_CONFIG_RX_DLL_DELAY rw — RX DLL Delay: This field determines the number of delay elements to insert on data path between ref_clk and rx_dll_clk.
    values as PHY_CONFIG_TX_DLL_DELAY
0xB8 phy_master_control reset not defined — PHY DLL Master Control Register
  [24] PHY_MASTER_LOCK_MODE rw — Determines if the master delay line locks on a full cycle or half cycle of delay.
    0=DISABLE; 1=ENABLE
  [23] PHY_MASTER_BYPASS_MODE rw — Controls the bypass mode of the master and slave DLLs.
    0=DISABLE; 1=ENABLE
  [22:20] PHY_MASTER_PHASE_DETECT_SELECTOR rw — Selects the number of delay elements to be inserted between the phase detect flip-flops.
    values as mode_bit_config.CHUNK_SIZE
  [18:16] PHY_MASTER_NB_INDICATIONS rw — Holds the number of consecutive increment or decrement indications.
    values as mode_bit_config.CHUNK_SIZE
  [6:0] PHY_MASTER_INITIAL_DELAY rw — This value is the initial delay value for the DLL.
    values as phy_configuration.PHY_CONFIG_TX_DLL_DELAY
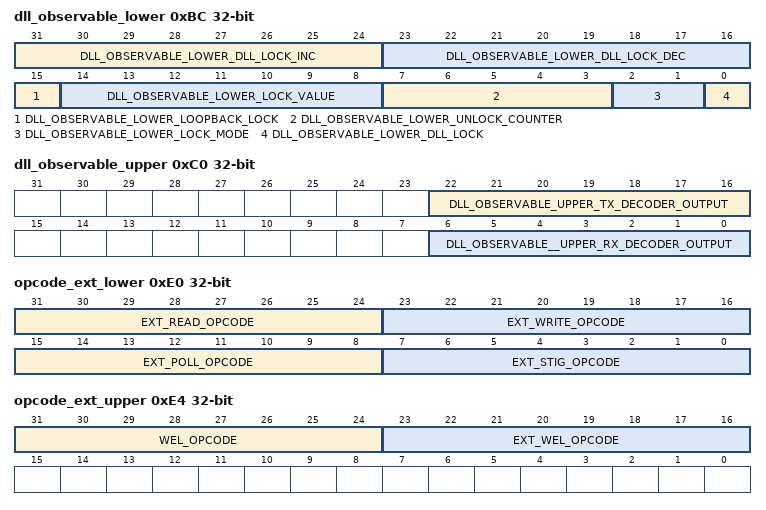
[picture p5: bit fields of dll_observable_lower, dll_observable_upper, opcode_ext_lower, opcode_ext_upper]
0xBC dll_observable_lower ro — DLL Observable Register Lower
  [31:24] DLL_OBSERVABLE_LOWER_DLL_LOCK_INC — Holds the state of the cumulative dll_lock_inc register.
    values as dev_instr_rd_config.RD_OPCODE_NON_XIP
  [23:16] DLL_OBSERVABLE_LOWER_DLL_LOCK_DEC — Holds the state of the cumulative dll_lock_dec register.
    values as dev_instr_rd_config.RD_OPCODE_NON_XIP
  [15] DLL_OBSERVABLE_LOWER_LOOPBACK_LOCK — This bit indicates that lock of loopback is done.
    0=DISABLE; 1=ENABLE
  [14:8] DLL_OBSERVABLE_LOWER_LOCK_VALUE — Reports the DLL encoder value from the master DLL to the slave DLLs.
    values as phy_configuration.PHY_CONFIG_TX_DLL_DELAY
  [7:3] DLL_OBSERVABLE_LOWER_UNLOCK_COUNTER — Reports the number of increments or decrements required for the master DLL to complete the locking process.
    values as dev_instr_rd_config.DUMMY_RD_CLK_CYCLES
  [2:1] DLL_OBSERVABLE_LOWER_LOCK_MODE — Defines the mode in which the DLL has achieved the lock.
    values as dev_instr_rd_config.DATA_XFER_TYPE_EXT_MODE
  [0] DLL_OBSERVABLE_LOWER_DLL_LOCK — Indicates status of DLL.
    0=DISABLE; 1=ENABLE
0xC0 dll_observable_upper ro — DLL Observable Register Upper
  [22:16] DLL_OBSERVABLE_UPPER_TX_DECODER_OUTPUT — Holds the encoded value for the TX delay line for this slice.
    values as phy_configuration.PHY_CONFIG_TX_DLL_DELAY
  [6:0] DLL_OBSERVABLE__UPPER_RX_DECODER_OUTPUT — Holds the encoded value for the RX delay line for this slice.
    values as phy_configuration.PHY_CONFIG_TX_DLL_DELAY
0xE0 opcode_ext_lower rw reset not defined — Opcode Extension Register (Lower)
  [all] fields
    values as dev_instr_rd_config.RD_OPCODE_NON_XIP
  [31:24] EXT_READ_OPCODE — Supplement byte of any Read Opcode
  [23:16] EXT_WRITE_OPCODE — Supplement byte of any Write Opcode
  [15:8] EXT_POLL_OPCODE — Supplement byte of any Polling Opcode
  [7:0] EXT_STIG_OPCODE — Supplement byte of any STIG Opcode
0xE4 opcode_ext_upper reset not defined — Opcode Extension Register (Upper)
  [31:24] WEL_OPCODE rw — First byte of any WEL Opcode
    values as dev_instr_rd_config.RD_OPCODE_NON_XIP
  [23:16] EXT_WEL_OPCODE rw — Supplement byte of any WEL Opcode
    values as dev_instr_rd_config.RD_OPCODE_NON_XIP
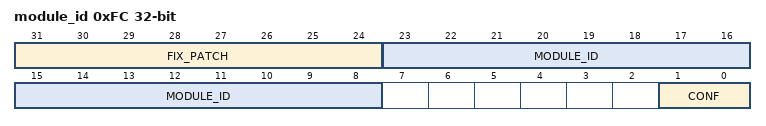
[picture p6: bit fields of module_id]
0xFC module_id ro reset not defined
  [31:24] FIX_PATCH — Fix/path number related to revision described by 3 LSBs of this register
    values as dev_instr_rd_config.RD_OPCODE_NON_XIP
  [23:8] MODULE_ID — Module/Revision ID number
    values as sram_fill.SRAM_FILL_INDAC_WRITE
  [1:0] CONF — Configuration ID number: 0 : OCTAL + PHY Configuration 1 : OCTAL Configuration 2 : QUAD + PHY Configuration 3 : QUAD Configuration
    values as dev_instr_rd_config.DATA_XFER_TYPE_EXT_MODE
